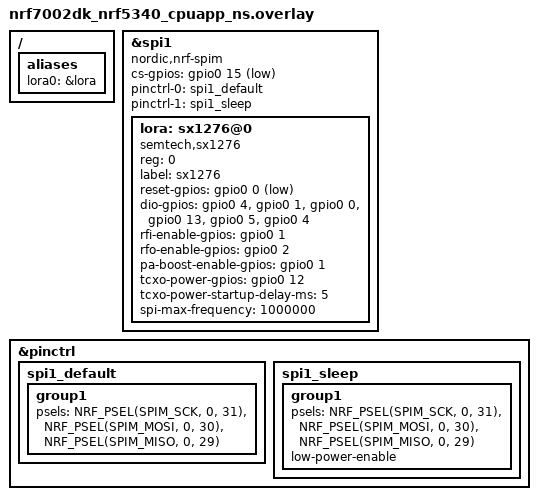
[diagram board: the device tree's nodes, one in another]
&spi1 {
    compatible = "nordic,nrf-spim";
    status = "okay";
    cs-gpios = <&gpio0 15 GPIO_ACTIVE_LOW>;

    pinctrl-0 = <&spi1_default>;
    pinctrl-1 = <&spi1_sleep>;
    pinctrl-names = "default", "sleep";

    lora: sx1276@0 {
        compatible = "semtech,sx1276";
        reg = <0>;
        label = "sx1276";
        reset-gpios = <&gpio0 0 GPIO_ACTIVE_LOW>;
        dio-gpios = <&gpio0 4 (GPIO_PULL_DOWN | GPIO_ACTIVE_HIGH)>,
                     <&gpio0 1 (GPIO_PULL_DOWN | GPIO_ACTIVE_HIGH)>,
                     <&gpio0 0 (GPIO_PULL_DOWN | GPIO_ACTIVE_HIGH)>,
                     <&gpio0 13 (GPIO_PULL_DOWN | GPIO_ACTIVE_HIGH)>,
                     <&gpio0 5 (GPIO_PULL_DOWN | GPIO_ACTIVE_HIGH)>,
                     <&gpio0 4 (GPIO_PULL_DOWN | GPIO_ACTIVE_HIGH)>;
        rfi-enable-gpios = <&gpio0 1 GPIO_ACTIVE_HIGH>;
        rfo-enable-gpios = <&gpio0 2 GPIO_ACTIVE_HIGH>;
        pa-boost-enable-gpios = <&gpio0 1 GPIO_ACTIVE_HIGH>;
        tcxo-power-gpios = <&gpio0 12 GPIO_ACTIVE_HIGH>;
        tcxo-power-startup-delay-ms = <5>;
        spi-max-frequency = <1000000>;
    };
};



&pinctrl {
	/omit-if-no-ref/ spi1_default: spi1_default {
		group1 {
			psels = <NRF_PSEL(SPIM_SCK, 0, 31)>,
				<NRF_PSEL(SPIM_MOSI, 0, 30)>,
				<NRF_PSEL(SPIM_MISO, 0, 29)>;
		};
	};

	/omit-if-no-ref/ spi1_sleep: spi1_sleep {
		group1 {
			psels = <NRF_PSEL(SPIM_SCK, 0, 31)>,
				<NRF_PSEL(SPIM_MOSI, 0, 30)>,
				<NRF_PSEL(SPIM_MISO, 0, 29)>;
			low-power-enable;
		};
	};
};

/ {
    aliases {
       lora0 = &lora;
  };
};
